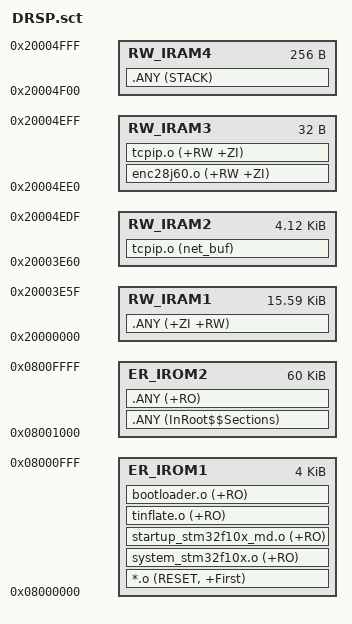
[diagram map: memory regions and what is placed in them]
; *************************************************************
; *** Scatter-Loading Description File generated by uVision ***
; *************************************************************

LR_IROM1 0x08000000 0x1000  {    ; load region size_region
	  ER_IROM1 0x08000000 0x1000 {  ; load address = execution address
		*.o (RESET, +First)
		system_stm32f10x.o (+RO)
		startup_stm32f10x_md.o (+RO)
		tinflate.o (+RO)
		bootloader.o (+RO)
		}
	}
 LR_IROM2 0x08001000 0x0F000  {  
	ER_IROM2 0x08001000 0x0F000 {
		;.ANY (.ARM.Collect$$$$00000000, +First)
		;__main.o (RO, +First)
		.ANY (InRoot$$Sections)
		.ANY (+RO)
	}

	RW_IRAM1 0x20000000 0x3E60  {
		.ANY (+ZI +RW)
	}
	  
	RW_IRAM2 0x20003E60 0x1080 {
		tcpip.o (net_buf)
	}
	
	RW_IRAM3 0x20004EE0 0x0020  {
		enc28j60.o (+RW +ZI)
		tcpip.o (+RW +ZI)
	}	
	
	RW_IRAM4 0x20004F00 0x0100  {
		.ANY (STACK)
	}
}
